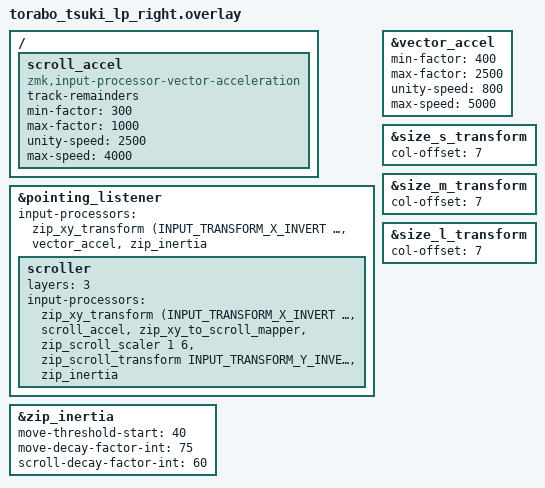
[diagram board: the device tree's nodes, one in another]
#include "torabo_tsuki_lp.dtsi"
#include <input/processors.dtsi>
#include <dt-bindings/zmk/input_transform.h>
#include <zmk-input-inertia/input/processor/input_inertia.dtsi>
#include <zmk-input-vector-acceleration/input_processor_vector_accel.dtsi>

&pointing_listener {
    input-processors = <&zip_xy_transform (INPUT_TRANSFORM_X_INVERT | INPUT_TRANSFORM_Y_INVERT)>,
                       <&vector_accel>,
                       <&zip_inertia>;

    scroller {
        layers = <3>;
        input-processors = <&zip_xy_transform (INPUT_TRANSFORM_X_INVERT | INPUT_TRANSFORM_Y_INVERT)>,
                           <&scroll_accel>,
                           <&zip_xy_to_scroll_mapper>,
                           <&zip_scroll_scaler 1 6>,
                           <&zip_scroll_transform INPUT_TRANSFORM_Y_INVERT>,
                           <&zip_inertia>;
    };
};

// A second, independent curve instance (same compatible as &vector_accel)
// dedicated to scrolling. max-factor is capped at 1000 (1.0x, no boost),
// so the peak stays exactly what zip_scroll_scaler already produces --
// only how EASILY that peak is reached changes: below unity-speed, slower
// motion is damped down to min-factor; a decisively fast flick is needed
// to reach unity-speed and get full, un-damped scroll output.
// Starting values -- retune on hardware (see commit message).
/ {
    scroll_accel: scroll_accel {
        compatible = "zmk,input-processor-vector-acceleration";
        status = "okay";
        #input-processor-cells = <0>;
        track-remainders;

        min-factor = <300>;
        max-factor = <1000>;
        unity-speed = <2500>;
        max-speed = <4000>;
    };
};

// Tuning: tame scroll speed/coast and avoid move-inertia overshoot on
// precise, deliberate cursor positioning (see commit message).
&zip_inertia {
    move-threshold-start = <40>;
    move-decay-factor-int = <75>;
    scroll-decay-factor-int = <60>;
};

// Acceleration curve for normal cursor movement: slow, deliberate motion
// is scaled down for precise small-target aiming, a fast flick is scaled
// up so full-screen traversal still takes little physical movement.
// Starting values -- retune on hardware (see commit message).
&vector_accel {
    min-factor = <400>;
    max-factor = <2500>;
    unity-speed = <800>;
    max-speed = <5000>;
};

&size_s_transform {
    col-offset = <7>;
};

&size_m_transform {
    col-offset = <7>;
};

&size_l_transform {
    col-offset = <7>;
};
